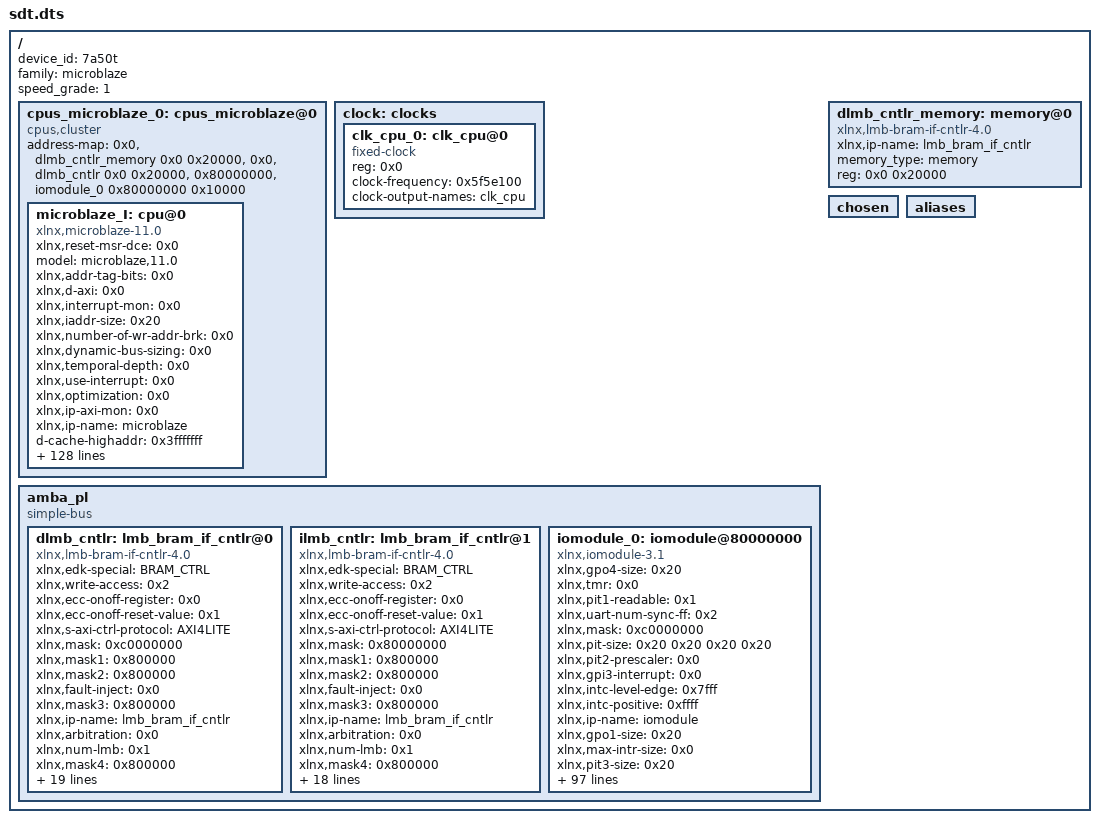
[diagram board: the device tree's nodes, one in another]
/dts-v1/;
/ {
        device_id = "7a50t";
        #address-cells = <0x1>;
        #size-cells = <0x1>;
        family = "microblaze";
        speed_grade = "1";

        cpus_microblaze_0: cpus_microblaze@0 {
                #cpu-mask-cells = <0x1>;
                compatible = "cpus,cluster";
                #address-cells = <0x1>;
                #size-cells = <0x0>;
                address-map = <0x0 &dlmb_cntlr_memory 0x0 0x20000>,
                 <0x0 &dlmb_cntlr 0x0 0x20000>,
                 <0x80000000 &iomodule_0 0x80000000 0x10000>;
                #ranges-address-cells = <0x1>;
                #ranges-size-cells = <0x1>;
                phandle = <0x5>;

                microblaze_I: cpu@0 {
                        xlnx,reset-msr-dce = <0x0>;
                        model = "microblaze,11.0";
                        xlnx,addr-tag-bits = <0x0>;
                        xlnx,d-axi = <0x0>;
                        xlnx,interrupt-mon = <0x0>;
                        xlnx,iaddr-size = <0x20>;
                        xlnx,number-of-wr-addr-brk = <0x0>;
                        xlnx,dynamic-bus-sizing = <0x0>;
                        xlnx,temporal-depth = <0x0>;
                        xlnx,use-interrupt = <0x0>;
                        xlnx,optimization = <0x0>;
                        xlnx,ip-axi-mon = <0x0>;
                        xlnx,ip-name = "microblaze";
                        d-cache-highaddr = <0x3fffffff>;
                        xlnx,dcache-force-tag-lutram = <0x0>;
                        xlnx,pc-width = <0x11>;
                        xlnx,interrupt-is-edge = <0x0>;
                        reg = <0x0>;
                        xlnx,async-interrupt = <0x1>;
                        xlnx,use-mmu = <0x0>;
                        xlnx,reset-msr-ee = <0x0>;
                        xlnx,icache-victims = <0x0>;
                        xlnx,use-reorder-instr = <0x0>;
                        xlnx,d-lmb-mon = <0x0>;
                        xlnx,d-lmb-protocol = <0x0>;
                        xlnx,ill-opcode-exception = <0x0>;
                        xlnx,dcache-always-used = <0x1>;
                        xlnx,use-div = <0x0>;
                        xlnx,dc-axi-mon = <0x0>;
                        xlnx,debug-trace-async-reset = <0x0>;
                        xlnx,trace = <0x0>;
                        xlnx,part = "xc7a50tcsg324-1";
                        i-cache-baseaddr = <0x0>;
                        xlnx,use-config-reset = <0x0>;
                        xlnx,pvr = <0x0>;
                        xlnx,i-lmb-mon = <0x0>;
                        xlnx,dcache-byte-size = <0x2000>;
                        xlnx,fault-tolerant = <0x0>;
                        xlnx,family = "artix7";
                        compatible = "xlnx,microblaze-11.0", "xlnx,microblaze";
                        xlnx,data-size = <0x20>;
                        xlnx,mmu-zones = <0x10>;
                        xlnx,debug-trace-size = <0x2000>;
                        xlnx,mmu-privileged-instr = <0x0>;
                        xlnx,enable-discrete-ports = <0x0>;
                        d-cache-line-size = <0x10>;
                        xlnx,d-lmb = <0x1>;
                        xlnx,sco = <0x0>;
                        xlnx,reset-msr-eip = <0x0>;
                        xlnx,debug-interface = <0x0>;
                        clock-frequency = <0x5f5e100>;
                        xlnx,use-ext-brk = <0x0>;
                        xlnx,daddr-size = <0x20>;
                        xlnx,debug-enabled = <0x0>;
                        xlnx,reset-msr-ice = <0x0>;
                        xlnx,num-sync-ff-dbg-trace-clk = <0x2>;
                        xlnx,i-lmb-protocol = <0x0>;
                        xlnx,endianness = <0x1>;
                        xlnx,fsl-exception = <0x0>;
                        i-cache-line-size = <0x10>;
                        xlnx,use-extended-fsl-instr = <0x0>;
                        xlnx,reset-msr = <0x0>;
                        xlnx,dp-axi-mon = <0x0>;
                        device_type = "cpu";
                        xlnx,branch-target-cache-size = <0x0>;
                        xlnx,dcache-use-writeback = <0x0>;
                        xlnx,div-zero-exception = <0x0>;
                        xlnx,mmu-tlb-access = <0x3>;
                        bus-handle = <0x4>;
                        xlnx,cache-byte-size = <0x2000>;
                        xlnx,pvr-user2 = <0x0>;
                        xlnx,opcode-0x0-illegal = <0x0>;
                        xlnx,icache-line-len = <0x4>;
                        xlnx,ecc-use-ce-exception = <0x0>;
                        xlnx,base-vectors = <0x0>;
                        xlnx,edk-special = "microblaze";
                        xlnx,use-dcache = <0x0>;
                        xlnx,use-barrel = <0x0>;
                        xlnx,reset-msr-bip = <0x0>;
                        xlnx,allow-dcache-wr = <0x1>;
                        xlnx,addr-size = <0x20>;
                        xlnx,debug-external-trace = <0x0>;
                        xlnx,piaddr-size = <0x20>;
                        i-cache-highaddr = <0x3fffffff>;
                        xlnx,num-sync-ff-clk-debug = <0x2>;
                        xlnx,debug-event-counters = <0x5>;
                        xlnx,fpu-exception = <0x0>;
                        xlnx,allow-icache-wr = <0x1>;
                        xlnx,g-use-exceptions = <0x0>;
                        xlnx,i-axi = <0x0>;
                        xlnx,g-template-list = <0x0>;
                        xlnx,icache-streams = <0x0>;
                        xlnx,dcache-line-len = <0x4>;
                        xlnx,num-sync-ff-clk = <0x2>;
                        xlnx,edk-iptype = "PROCESSOR";
                        xlnx,use-stack-protection = <0x0>;
                        xlnx,use-hw-mul = <0x0>;
                        xlnx,num-sync-ff-dbg-clk = <0x1>;
                        xlnx,interconnect = <0x2>;
                        xlnx,debug-latency-counters = <0x1>;
                        i-cache-size = <0x2000>;
                        xlnx,exceptions-in-delay-slots = <0x1>;
                        xlnx,use-fpu = <0x0>;
                        xlnx,reset-msr-ie = <0x0>;
                        xlnx,edge-is-positive = <0x1>;
                        xlnx,use-pcmp-instr = <0x0>;
                        xlnx,use-icache = <0x0>;
                        d-cache-size = <0x2000>;
                        xlnx,memory-ip-list = "ilmb_cntlr_memory", "dlmb_cntlr_memory";
                        xlnx,async-wakeup = <0x3>;
                        xlnx,use-non-secure = <0x0>;
                        xlnx,dcache-addr-tag = <0x0>;
                        xlnx,number-of-rd-addr-brk = <0x0>;
                        d-cache-baseaddr = <0x0>;
                        xlnx,area-optimized = <0x1>;
                        xlnx,avoid-primitives = <0x0>;
                        xlnx,lockstep-slave = <0x0>;
                        xlnx,use-ext-nm-brk = <0x0>;
                        xlnx,instr-size = <0x20>;
                        xlnx,icache-always-used = <0x1>;
                        xlnx,i-lmb = <0x1>;
                        xlnx,mmu-dtlb-size = <0x4>;
                        xlnx,lockstep-select = <0x0>;
                        xlnx,lmb-data-size = <0x20>;
                        xlnx,ic-axi-mon = <0x0>;
                        xlnx,enable-conversion = <0x1>;
                        xlnx,num-sync-ff-clk-irq = <0x1>;
                        xlnx,fsl-links = <0x0>;
                        timebase-frequency = <0x5f5e100>;
                        xlnx,icache-force-tag-lutram = <0x0>;
                        xlnx,dcache-data-width = <0x0>;
                        xlnx,dcache-victims = <0x0>;
                        xlnx,use-branch-target-cache = <0x0>;
                        xlnx,debug-profile-size = <0x0>;
                        xlnx,unaligned-exceptions = <0x0>;
                        xlnx,lockstep-master = <0x0>;
                        xlnx,freq = <0x5f5e100>;
                        xlnx,number-of-pc-brk = <0x1>;
                        xlnx,mmu-itlb-size = <0x2>;
                        xlnx,imprecise-exceptions = <0x0>;
                        xlnx,use-msr-instr = <0x0>;
                        xlnx,icache-data-width = <0x0>;
                        xlnx,debug-counter-width = <0x20>;
                        phandle = <0x6>;
                };
        };

        clock: clocks {
                #address-cells = <0x1>;
                #size-cells = <0x0>;
                phandle = <0x7>;

                clk_cpu_0: clk_cpu@0 {
                        compatible = "fixed-clock";
                        reg = <0x0>;
                        clock-frequency = <0x5f5e100>;
                        clock-output-names = "clk_cpu";
                        #clock-cells = <0x0>;
                        phandle = <0x8>;
                };
        };

        amba_pl: amba_pl {
                ranges;
                compatible = "simple-bus";
                #address-cells = <0x1>;
                #size-cells = <0x1>;
                phandle = <0x4>;

                dlmb_cntlr: lmb_bram_if_cntlr@0 {
                        xlnx,edk-special = "BRAM_CTRL";
                        xlnx,write-access = <0x2>;
                        compatible = "xlnx,lmb-bram-if-cntlr-4.0", "xlnx,axi-bram-ctrl";
                        xlnx,ecc-onoff-register = <0x0>;
                        xlnx,ecc-onoff-reset-value = <0x1>;
                        xlnx,s-axi-ctrl-protocol = "AXI4LITE";
                        xlnx,mask = <0xc0000000>;
                        xlnx,mask1 = <0x800000>;
                        xlnx,mask2 = <0x800000>;
                        xlnx,fault-inject = <0x0>;
                        xlnx,mask3 = <0x800000>;
                        xlnx,ip-name = "lmb_bram_if_cntlr";
                        xlnx,arbitration = <0x0>;
                        xlnx,num-lmb = <0x1>;
                        xlnx,mask4 = <0x800000>;
                        reg = <0x0 0x20000>;
                        xlnx,s-axi-ctrl-addr-width = <0x20>;
                        xlnx,mask5 = <0x800000>;
                        xlnx,ecc-status-registers = <0x0>;
                        xlnx,mask6 = <0x800000>;
                        xlnx,lmb-protocol = <0x0>;
                        xlnx,ce-counter-width = <0x0>;
                        xlnx,mask7 = <0x800000>;
                        xlnx,ecc = <0x0>;
                        xlnx,edk-iptype = "PERIPHERAL";
                        xlnx,lmb-dwidth = <0x20>;
                        xlnx,interconnect = <0x0>;
                        xlnx,ce-failing-registers = <0x0>;
                        xlnx,ue-failing-registers = <0x0>;
                        status = "okay";
                        xlnx,data-width = <0x20>;
                        xlnx,s-axi-ctrl-data-width = <0x20>;
                        xlnx,bram-awidth = <0x20>;
                        xlnx,lmb-awidth = <0x20>;
                        xlnx,name = "dlmb_cntlr";
                        phandle = <0x2>;
                };

                ilmb_cntlr: lmb_bram_if_cntlr@1 {
                        xlnx,edk-special = "BRAM_CTRL";
                        xlnx,write-access = <0x2>;
                        compatible = "xlnx,lmb-bram-if-cntlr-4.0", "xlnx,axi-bram-ctrl";
                        xlnx,ecc-onoff-register = <0x0>;
                        xlnx,ecc-onoff-reset-value = <0x1>;
                        xlnx,s-axi-ctrl-protocol = "AXI4LITE";
                        xlnx,mask = <0x80000000>;
                        xlnx,mask1 = <0x800000>;
                        xlnx,mask2 = <0x800000>;
                        xlnx,fault-inject = <0x0>;
                        xlnx,mask3 = <0x800000>;
                        xlnx,ip-name = "lmb_bram_if_cntlr";
                        xlnx,arbitration = <0x0>;
                        xlnx,num-lmb = <0x1>;
                        xlnx,mask4 = <0x800000>;
                        reg = <0x0 0x20000>;
                        xlnx,s-axi-ctrl-addr-width = <0x20>;
                        xlnx,mask5 = <0x800000>;
                        xlnx,ecc-status-registers = <0x0>;
                        xlnx,mask6 = <0x800000>;
                        xlnx,lmb-protocol = <0x0>;
                        xlnx,ce-counter-width = <0x0>;
                        xlnx,mask7 = <0x800000>;
                        xlnx,ecc = <0x0>;
                        xlnx,edk-iptype = "PERIPHERAL";
                        xlnx,lmb-dwidth = <0x20>;
                        xlnx,interconnect = <0x0>;
                        xlnx,ce-failing-registers = <0x0>;
                        xlnx,ue-failing-registers = <0x0>;
                        status = "okay";
                        xlnx,s-axi-ctrl-data-width = <0x20>;
                        xlnx,bram-awidth = <0x20>;
                        xlnx,lmb-awidth = <0x20>;
                        xlnx,name = "ilmb_cntlr";
                        phandle = <0x9>;
                };

                iomodule_0: iomodule@80000000 {
                        xlnx,gpo4-size = <0x20>;
                        xlnx,tmr = <0x0>;
                        xlnx,pit1-readable = <0x1>;
                        xlnx,uart-num-sync-ff = <0x2>;
                        xlnx,mask = <0xc0000000>;
                        xlnx,pit-size = <0x20 0x20 0x20 0x20>;
                        xlnx,pit2-prescaler = <0x0>;
                        xlnx,gpi3-interrupt = <0x0>;
                        xlnx,intc-level-edge = <0x7fff>;
                        xlnx,intc-positive = <0xffff>;
                        xlnx,ip-name = "iomodule";
                        xlnx,gpo1-size = <0x20>;
                        xlnx,max-intr-size = <0x0>;
                        xlnx,pit3-size = <0x20>;
                        xlnx,fit3-interrupt = <0x0>;
                        reg = <0x80000000 0x10000 0xc0000000 0x40000000>;
                        xlnx,fit1-no-clocks = <0x1848>;
                        xlnx,gpi2-size = <0x20>;
                        xlnx,pit2-readable = <0x1>;
                        xlnx,intc-irq-connection = <0x0>;
                        xlnx,uart-tx-interrupt = <0x0>;
                        xlnx,use-config-reset = <0x0>;
                        xlnx,pit2-interrupt = <0x0>;
                        xlnx,intc-base-vectors = <0x0>;
                        compatible = "xlnx,iomodule-3.1";
                        xlnx,gpo4-init = <0x0>;
                        xlnx,pit3-readable = <0x1>;
                        xlnx,pit3-prescaler = <0x0>;
                        xlnx,gpi4-interrupt = <0x0>;
                        xlnx,gpo1-init = <0x0>;
                        xlnx,use-io-bus = <0x1>;
                        xlnx,use-gpo1 = <0x0>;
                        xlnx,uart-baudrate = <0x2580>;
                        xlnx,fit4-interrupt = <0x0>;
                        xlnx,gpo3-size = <0x20>;
                        xlnx,use-gpo2 = <0x0>;
                        xlnx,uart-data-bits = <0x8>;
                        xlnx,lmb-protocol = <0x0>;
                        xlnx,pit-prescaler = <0x0 0x0 0x0 0x0>;
                        xlnx,gpio1-board-interface = "Custom";
                        xlnx,use-gpo3 = <0x0>;
                        xlnx,fit2-no-clocks = <0x1848>;
                        xlnx,options = <0x1>;
                        xlnx,gpio2-board-interface = "Custom";
                        xlnx,use-gpo4 = <0x0>;
                        xlnx,gpi4-size = <0x20>;
                        xlnx,gpio3-board-interface = "Custom";
                        xlnx,uart-rx-interrupt = <0x0>;
                        xlnx,uart-error-interrupt = <0x0>;
                        xlnx,gpio4-board-interface = "Custom";
                        xlnx,pit4-readable = <0x1>;
                        status = "okay";
                        xlnx,intc-use-irq-out = <0x1>;
                        xlnx,clock-freq = <0x5f5e100>;
                        xlnx,gpo-init = <0x0 0x0 0x0 0x0>;
                        xlnx,pit2-size = <0x20>;
                        xlnx,intc-intr-size = <0x1>;
                        xlnx,intc-use-ext-intr = <0x0>;
                        xlnx,name = "iomodule_0";
                        xlnx,gpi1-size = <0x20>;
                        xlnx,pit3-interrupt = <0x0>;
                        xlnx,intc-has-fast = <0x1>;
                        xlnx,pit-used = <0x0 0x0 0x0 0x0>;
                        xlnx,use-gpi1 = <0x0>;
                        xlnx,gpi1-interrupt = <0x0>;
                        xlnx,use-gpi2 = <0x0>;
                        xlnx,use-gpi3 = <0x0>;
                        xlnx,use-gpi4 = <0x0>;
                        xlnx,fit1-interrupt = <0x0>;
                        xlnx,uart-async = <0x0>;
                        xlnx,pit4-prescaler = <0x0>;
                        xlnx,gpo3-init = <0x0>;
                        xlnx,intc-addr-width = <0x11>;
                        xlnx,edk-iptype = "PERIPHERAL";
                        xlnx,fit3-no-clocks = <0x1848>;
                        xlnx,use-uart-rx = <0x0>;
                        xlnx,pit-mask = <0xffffffff 0xffffffff 0xffffffff 0xffffffff>;
                        xlnx,uart-prog-baudrate = <0x0>;
                        xlnx,uart-freq = <0x5f5e100>;
                        xlnx,use-pit1 = <0x0>;
                        xlnx,gpo2-size = <0x20>;
                        xlnx,use-pit2 = <0x0>;
                        xlnx,pit4-size = <0x20>;
                        xlnx,pit-readable = <0x1 0x1 0x1 0x1>;
                        xlnx,use-pit3 = <0x0>;
                        xlnx,use-pit4 = <0x0>;
                        xlnx,pit4-interrupt = <0x0>;
                        xlnx,gpi3-size = <0x20>;
                        xlnx,intc-async-intr = <0xffff>;
                        xlnx,pit1-prescaler = <0x0>;
                        xlnx,avoid-primitives = <0x0>;
                        xlnx,gpi2-interrupt = <0x0>;
                        xlnx,io-bus-error-signals = <0x0>;
                        xlnx,use-tmr-disable = <0x0>;
                        xlnx,use-fit1 = <0x0>;
                        xlnx,pit1-size = <0x20>;
                        xlnx,intc-num-sync-ff = <0x2>;
                        xlnx,uart-board-interface = "Custom";
                        xlnx,use-fit2 = <0x0>;
                        xlnx,fit2-interrupt = <0x0>;
                        xlnx,use-fit3 = <0x0>;
                        xlnx,use-fit4 = <0x0>;
                        xlnx,uart-use-parity = <0x0>;
                        xlnx,lmb-dwidth = <0x20>;
                        xlnx,fit4-no-clocks = <0x1848>;
                        xlnx,uart-odd-parity = <0x0>;
                        xlnx,freq = <0x5f5e100>;
                        xlnx,use-uart-tx = <0x0>;
                        xlnx,pit1-interrupt = <0x0>;
                        xlnx,gpo2-init = <0x0>;
                        xlnx,io-mask = <0xc0000000>;
                        xlnx,lmb-awidth = <0x20>;
                        phandle = <0x3>;
                };
        };

        dlmb_cntlr_memory: memory@0 {
                compatible = "xlnx,lmb-bram-if-cntlr-4.0";
                xlnx,ip-name = "lmb_bram_if_cntlr";
                device_type = "memory";
                memory_type = "memory";
                reg = <0x0 0x20000>;
                phandle = <0x1>;
        };

        chosen {
        };

        aliases {
        };

        __symbols__ {
                cpus_microblaze_0 = "/cpus_microblaze@0";
                microblaze_I = "/cpus_microblaze@0/cpu@0";
                clock = "/clocks";
                clk_cpu_0 = "/clocks/clk_cpu@0";
                amba_pl = "/amba_pl";
                dlmb_cntlr = "/amba_pl/lmb_bram_if_cntlr@0";
                ilmb_cntlr = "/amba_pl/lmb_bram_if_cntlr@1";
                iomodule_0 = "/amba_pl/iomodule@80000000";
                dlmb_cntlr_memory = "/memory@0";
        };
};
